# WKUP_CTRL_MMR0_CFG0 register map
Vendor: Texas Instruments
Registers are 32-bit, read-write, reset 0x0 unless marked. A register's access mark holds for its fields unless they carry their own. Offsets are as the file gives them; [hi:lo] are bit positions; lines under a group give offsets from that group; {n}, {i} and the like mark numbered series.

## WKUP_CTRL_MMR0_CFG0 (part 4 of 11)
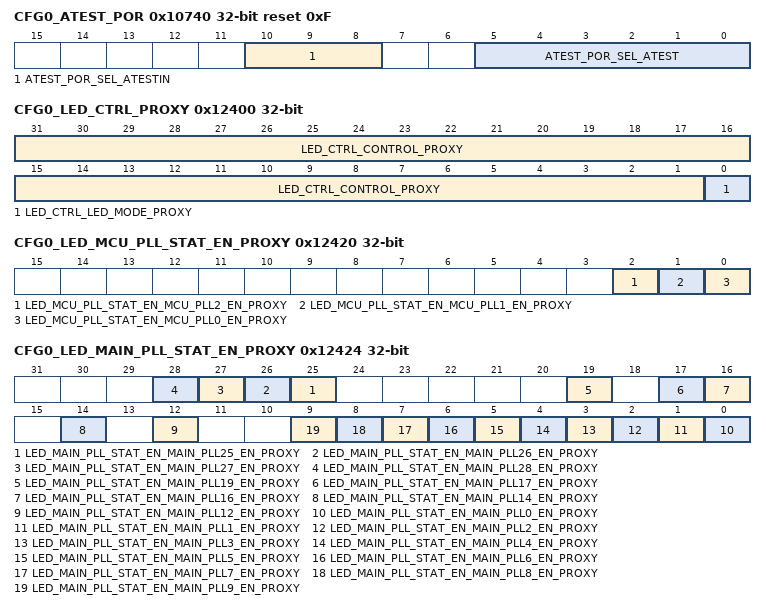
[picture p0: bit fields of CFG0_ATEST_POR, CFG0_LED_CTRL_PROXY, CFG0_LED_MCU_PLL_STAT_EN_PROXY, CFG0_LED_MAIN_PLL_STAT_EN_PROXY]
0x10740 CFG0_ATEST_POR reset 0xF
  [10:8] ATEST_POR_SEL_ATESTIN — Test select 3'b000 - Test Modes 0-4, See sel_atest value 3'b001 - Test Mode 5 when sel_atest = 6'b001111 Others - N/A (Hi-Z at ATEST_OUT)
  [5:0] ATEST_POR_SEL_ATEST — Test select 6'b000000 to 001010 - Bandgap TestT (Test Mode 1) 6'b001001 to 001111 - Hi-Z (when sel_atestin = 3'b000) 6'b001001 to 001111 - HVPOR Test (when sel_atestin = 3'b001) 6'b01xx00 to 01xx11 - POKHV Test (Test Mode 2) 6'b10xx00 to 10xx11 - POKLVA Test (Test mode 3) 6'b11xx00 - 11xx11 - POKLVB Test (Test Mode 4)
0x10744 CFG0_ATEST_POK_VDDA_MCU_UV_CTRL
  [2:0] ATEST_POK_VDDA_MCU_UV_CTRL_POK_ATMUXSEL — Analog test mux select 2'b000 - HI-Z 2'b001 - IREF 2'b101 - VREF 2'b111 - RESDIV_VREF
0x10748 CFG0_ATEST_POK_VDDA_MCU_OV_CTRL
  [2:0] ATEST_POK_VDDA_MCU_OV_CTRL_POK_ATMUXSEL — Analog test mux select 2'b000 - HI-Z 2'b001 - IREF 2'b101 - VREF 2'b111 - RESDIV_VREF
0x1074C CFG0_ATEST_POK_VDD_MCU_UV_CTRL
  [2:0] ATEST_POK_VDD_MCU_UV_CTRL_POK_ATMUXSEL — Analog test mux select 2'b000 - HI-Z 2'b001 - IREF 2'b101 - VREF 2'b111 - RESDIV_VREF
0x10750 CFG0_ATEST_POK_VDDA_PMIC_IN
  [2:0] ATEST_POK_VDDA_PMIC_IN_POK_ATMUXSEL — Analog test mux select 2'b000 - HI-Z 2'b001 - IREF 2'b101 - VREF 2'b111 - RESDIV_VREF
0x10754 CFG0_ATEST_POK_VDD_MCU_OV_CTRL
  [2:0] ATEST_POK_VDD_MCU_OV_CTRL_POK_ATMUXSEL — Analog test mux select 2'b000 - HI-Z 2'b001 - IREF 2'b101 - VREF 2'b111 - RESDIV_VREF
0x10760 CFG0_ATEST_POK_VDDSHV_WKUP_GEN_CTRL
  [2:0] ATEST_POK_VDDSHV_WKUP_GEN_CTRL_POK_ATMUXSEL — Analog test mux select 2'b000 - HI-Z 2'b001 - IREF 2'b101 - VREF 2'b111 - RESDIV_VREF
0x10764 CFG0_ATEST_POK_VDDR_MCU_CTRL
  [2:0] ATEST_POK_VDDR_MCU_CTRL_POK_ATMUXSEL — Analog test mux select 2'b000 - HI-Z 2'b001 - IREF 2'b101 - VREF 2'b111 - RESDIV_VREF
0x10768 CFG0_ATEST_POK_VMON_CAP_MCU_GEN_CTRL
  [2:0] ATEST_POK_VMON_CAP_MCU_GEN_CTRL_POK_ATMUXSEL — Analog test mux select 2'b000 - HI-Z 2'b001 - IREF 2'b101 - VREF 2'b111 - RESDIV_VREF
0x10780 CFG0_ATEST_POK_VDD_CORE_CTRL
  [2:0] ATEST_POK_VDD_CORE_CTRL_POK_ATMUXSEL — Analog test mux select 2'b000 - HI-Z 2'b001 - IREF 2'b101 - VREF 2'b111 - RESDIV_VREF
0x10784 CFG0_ATEST_POK_VDD_CPU_CTRL
  [2:0] ATEST_POK_VDD_CPU_CTRL_POK_ATMUXSEL — Analog test mux select 2'b000 - HI-Z 2'b001 - IREF 2'b101 - VREF 2'b111 - RESDIV_VREF
0x10788 CFG0_ATEST_POK_VMON_EXT_CTRL
  [2:0] ATEST_POK_VMON_EXT_CTRL_POK_ATMUXSEL — Analog test mux select 2'b000 - HI-Z 2'b001 - IREF 2'b101 - VREF 2'b111 - RESDIV_VREF
0x1078C CFG0_ATEST_POK_VDDR_CORE_CTRL
  [2:0] ATEST_POK_VDDR_CORE_CTRL_POK_ATMUXSEL — Analog test mux select 2'b000 - HI-Z 2'b001 - IREF 2'b101 - VREF 2'b111 - RESDIV_VREF
0x10790 CFG0_ATEST_POK_VMON_EXT_MAIN1P8_CTRL
  [2:0] ATEST_POK_VMON_EXT_MAIN1P8_CTRL_POK_ATMUXSEL — Analog test mux select 2'b000 - HI-Z 2'b001 - IREF 2'b101 - VREF 2'b111 - RESDIV_VREF
0x10794 CFG0_ATEST_POK_VMON_EXT_MAIN3P3_CTRL
  [2:0] ATEST_POK_VMON_EXT_MAIN3P3_CTRL_POK_ATMUXSEL — Analog test mux select 2'b000 - HI-Z 2'b001 - IREF 2'b101 - VREF 2'b111 - RESDIV_VREF
0x10798 CFG0_ATEST_POK_VDD_CPU1_CTRL
  [2:0] ATEST_POK_VDD_CPU1_CTRL_POK_ATMUXSEL — Analog test mux select 2'b000 - HI-Z 2'b001 - IREF 2'b101 - VREF 2'b111 - RESDIV_VREF
{0x11100+4i} CFG0_CLAIMREG_P4_R{i}_READONLY ro (i=0..15)
  [31:0] CLAIMREG_P4_R{i}_READONLY — Claim bits for Partition 4
{0x12000+4i} CFG0_DV_REG{i}_PROXY (i=0..63)
  [31:0] DV_REG{i}_BIT_PROXY — Defined by DV usage
{0x12200+4i} CFG0_DV_REG{i}_SET_PROXY access not given (i=0..31)
  [31:0] DV_REG{i}_SET_BIT_PROXY — Defined by DV usage (access R/W1TS)
{0x12300+4i} CFG0_DV_REG{i}_CLR_PROXY access not given (i=0..31)
  [31:0] DV_REG{i}_CLR_BIT_PROXY — Defined by DV usage (access R/W1TC)
0x12400 CFG0_LED_CTRL_PROXY access per field
  [31:1] LED_CTRL_CONTROL_PROXY rw — Test control
  [0] LED_CTRL_LED_MODE_PROXY ro — LED mode from decoded enable key
0x12408 CFG0_LED_ENABLE_PROXY
  [31:0] LED_ENABLE_ENABLE_KEY_PROXY — LED mode entry key 32'h204C4544 - Set PADCONFIG registers to LED mode values others - PADCONFIG registers retain programmed values
0x12420 CFG0_LED_MCU_PLL_STAT_EN_PROXY
  [2] LED_MCU_PLL_STAT_EN_MCU_PLL2_EN_PROXY — Enable MCU_PLL2 lockloss in status generation
  [1] LED_MCU_PLL_STAT_EN_MCU_PLL1_EN_PROXY — Enable MCU_PLL1 lockloss in status generation
  [0] LED_MCU_PLL_STAT_EN_MCU_PLL0_EN_PROXY — Enable MCU_PLL0 lockloss in status generation
0x12424 CFG0_LED_MAIN_PLL_STAT_EN_PROXY
  [n] LED_MAIN_PLL_STAT_EN_MAIN_PLL{n}_EN_PROXY (n=25..28) — Enable MAIN_PLL{n} lockloss in status generation
  [19] LED_MAIN_PLL_STAT_EN_MAIN_PLL19_EN_PROXY — Enable MAIN_PLL19 lockloss in status generation
  [17] LED_MAIN_PLL_STAT_EN_MAIN_PLL17_EN_PROXY — Enable MAIN_PLL17 lockloss in status generation
  [16] LED_MAIN_PLL_STAT_EN_MAIN_PLL16_EN_PROXY — Enable MAIN_PLL16 lockloss in status generation
  [14] LED_MAIN_PLL_STAT_EN_MAIN_PLL14_EN_PROXY — Enable MAIN_PLL14 lockloss in status generation
  [12] LED_MAIN_PLL_STAT_EN_MAIN_PLL12_EN_PROXY — Enable MAIN_PLL12 lockloss in status generation
  [n] LED_MAIN_PLL_STAT_EN_MAIN_PLL{n}_EN_PROXY (n=0..9) — Enable MAIN_PLL{n} lockloss in status generation
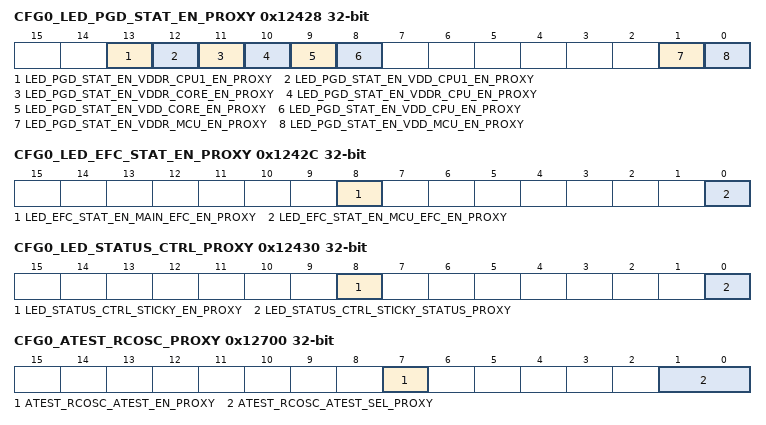
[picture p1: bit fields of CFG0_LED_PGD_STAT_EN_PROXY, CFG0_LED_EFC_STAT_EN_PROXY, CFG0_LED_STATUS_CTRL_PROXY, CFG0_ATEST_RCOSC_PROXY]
0x12428 CFG0_LED_PGD_STAT_EN_PROXY
  [13] LED_PGD_STAT_EN_VDDR_CPU1_EN_PROXY — Enable vddr_cpu1 PGD in status generation
  [12] LED_PGD_STAT_EN_VDD_CPU1_EN_PROXY — Enable vdd_cpu1 PGD in status generation
  [11] LED_PGD_STAT_EN_VDDR_CORE_EN_PROXY — Enable vddr_core PGD in status generation
  [10] LED_PGD_STAT_EN_VDDR_CPU_EN_PROXY — Enable vddr_cpu PGD in status generation
  [9] LED_PGD_STAT_EN_VDD_CORE_EN_PROXY — Enable vdd_core PGD in status generation
  [8] LED_PGD_STAT_EN_VDD_CPU_EN_PROXY — Enable vdd_cpu PGD in status generation
  [1] LED_PGD_STAT_EN_VDDR_MCU_EN_PROXY — Enable vddr_mcu PGD in status generation
  [0] LED_PGD_STAT_EN_VDD_MCU_EN_PROXY — Enable vdd_mcu PGD in status generation
0x1242C CFG0_LED_EFC_STAT_EN_PROXY
  [8] LED_EFC_STAT_EN_MAIN_EFC_EN_PROXY — Enable MAIN eFuse Ctrl PGD in status generation
  [0] LED_EFC_STAT_EN_MCU_EFC_EN_PROXY — Enable MCU eFuse Ctrl PGD in status generation
0x12430 CFG0_LED_STATUS_CTRL_PROXY
  [8] LED_STATUS_CTRL_STICKY_EN_PROXY — Sticky status enable. Selects which version of status to output on the pin. 0 - Use real-time status signal 1 - Use sticky status signal
  [0] LED_STATUS_CTRL_STICKY_STATUS_PROXY — Sticky status bit. This bit captures the falling edge of the status signal
{0x12480+4i} CFG0_SIM_CFG{i}_PROXY (i=0..7)
  [31:0] SIM_CFG{i}_CFG_INFO_PROXY — Model configuration info. Bit usage is determined by AVV team.
0x12500 CFG0_WKUP_MRGN_MODE0_PROXY
  [11:0] WKUP_MRGN_MODE0_HS2PARF_MEM_MRGN_ASST_PROXY — DFT memory margin control Bits 0-3 - dft_mem_margin Bits 4-5 - dft_mem_ra Bits 6-8 - dft_mem_wa Bits 9-11 - dft_wpulse
0x12504 CFG0_WKUP_MRGN_MODE1_PROXY
  [11:0] WKUP_MRGN_MODE1_HDDP_MEM_MRGN_ASST_PROXY — DFT memory margin control Bits 0-3 - dft_mem_margin Bits 4-5 - dft_mem_ra Bits 6-8 - dft_mem_wa Bits 9-11 - dft_wpulse
0x12508 CFG0_WKUP_MRGN_MODE2_PROXY
  [11:0] WKUP_MRGN_MODE2_EHDSP_MEM_MRGN_ASST_PROXY — DFT memory margin control Bits 0-3 - dft_mem_margin Bits 4-5 - dft_mem_ra Bits 6-8 - dft_mem_wa Bits 9-11 - dft_wpulse
0x1250C CFG0_WKUP_MRGN_MODE3_PROXY
  [11:0] WKUP_MRGN_MODE3_HD2PRF_MEM_MRGN_ASST_PROXY — DFT memory margin control Bits 0-3 - dft_mem_margin Bits 4-5 - dft_mem_ra Bits 6-8 - dft_mem_wa Bits 9-11 - dft_wpulse
0x12510 CFG0_WKUP_MRGN_MODE4_PROXY
  [11:0] WKUP_MRGN_MODE4_UHD2PRF_MEM_MRGN_ASST_PROXY — DFT memory margin control Bits 0-3 - dft_mem_margin Bits 4-5 - dft_mem_ra Bits 6-8 - dft_mem_wa Bits 9-11 - dft_wpulse
0x12514 CFG0_WKUP_MRGN_MODE5_PROXY
  [11:0] WKUP_MRGN_MODE5_ROM_MEM_MRGN_ASST_PROXY — DFT memory margin control Bits 0-3 - dft_mem_margin Bits 4-5 - dft_mem_ra Bits 6-8 - dft_mem_wa Bits 9-11 - dft_wpulse
0x12518 CFG0_WKUP_MRGN_MODE6_PROXY
  [11:0] WKUP_MRGN_MODE6_HDSP_MEM_MRGN_ASST_PROXY — DFT memory margin control Bits 0-3 - dft_mem_margin Bits 4-5 - dft_mem_ra Bits 6-8 - dft_mem_wa Bits 9-11 - dft_wpulse
0x1251C CFG0_WKUP_MRGN_MODE7_PROXY
  [11:0] WKUP_MRGN_MODE7_HSSP_MEM_MRGN_ASST_PROXY — DFT memory margin control Bits 0-3 - dft_mem_margin Bits 4-5 - dft_mem_ra Bits 6-8 - dft_mem_wa Bits 9-11 - dft_wpulse
0x12520 CFG0_WKUP_MRGN_MODE8_PROXY
  [11:0] WKUP_MRGN_MODE8_HD1PRF_MEM_MRGN_ASST_PROXY — DFT memory margin control Bits 0-3 - dft_mem_margin Bits 4-5 - dft_mem_ra Bits 6-8 - dft_mem_wa Bits 9-11 - dft_wpulse
0x12524 CFG0_WKUP_MRGN_MODE9_PROXY
  [11:0] WKUP_MRGN_MODE9_HS1PRF_MEM_MRGN_ASST_PROXY — DFT memory margin control Bits 0-3 - dft_mem_margin Bits 4-5 - dft_mem_ra Bits 6-8 - dft_mem_wa Bits 9-11 - dft_wpulse
0x12700 CFG0_ATEST_RCOSC_PROXY
  [7] ATEST_RCOSC_ATEST_EN_PROXY — Test enable 1'b0 - Disable (atestout is floating) 1'b1 - Enable (see atest_test)
  [1:0] ATEST_RCOSC_ATEST_SEL_PROXY — Test select When atest_en = 1 2'b0x - Hi-Z (Test 3) 2'b10 - Bias current (Test 1) 2'b11 - VREF (Test 2)
0x12720 CFG0_ATEST_HFOSC0_PROXY
  [0] ATEST_HFOSC0_TEST_EN_C_PROXY — Test enable 1'b0 - Output test current disabled 1'b1 - Test current enabled
0x12724 CFG0_ATEST_HFOSC1_PROXY
  [0] ATEST_HFOSC1_TEST_EN_C_PROXY — Test enable 1'b0 - Output test current disabled 1'b1 - Test current enabled
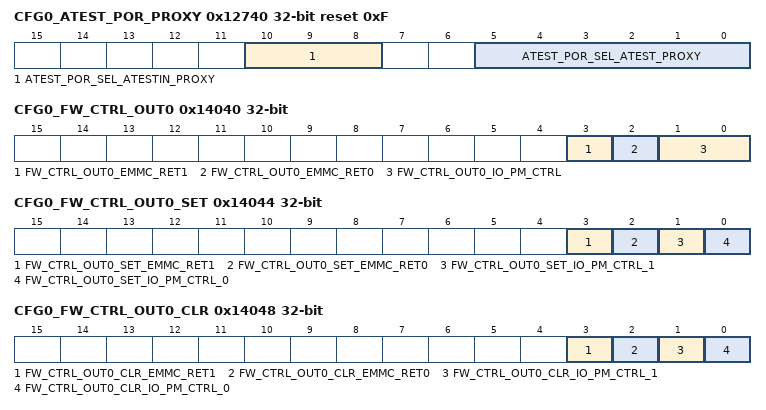
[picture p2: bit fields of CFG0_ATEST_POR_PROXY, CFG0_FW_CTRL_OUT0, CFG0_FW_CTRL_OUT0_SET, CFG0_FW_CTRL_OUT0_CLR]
0x12740 CFG0_ATEST_POR_PROXY reset 0xF
  [10:8] ATEST_POR_SEL_ATESTIN_PROXY — Test select 3'b000 - Test Modes 0-4, See sel_atest value 3'b001 - Test Mode 5 when sel_atest = 6'b001111 Others - N/A (Hi-Z at ATEST_OUT)
  [5:0] ATEST_POR_SEL_ATEST_PROXY — Test select 6'b000000 to 001010 - Bandgap TestT (Test Mode 1) 6'b001001 to 001111 - Hi-Z (when sel_atestin = 3'b000) 6'b001001 to 001111 - HVPOR Test (when sel_atestin = 3'b001) 6'b01xx00 to 01xx11 - POKHV Test (Test Mode 2) 6'b10xx00 to 10xx11 - POKLVA Test (Test mode 3) 6'b11xx00 - 11xx11 - POKLVB Test (Test Mode 4)
0x12744 CFG0_ATEST_POK_VDDA_MCU_UV_CTRL_PROXY
  [2:0] ATEST_POK_VDDA_MCU_UV_CTRL_POK_ATMUXSEL_PROXY — Analog test mux select 2'b000 - HI-Z 2'b001 - IREF 2'b101 - VREF 2'b111 - RESDIV_VREF
0x12748 CFG0_ATEST_POK_VDDA_MCU_OV_CTRL_PROXY
  [2:0] ATEST_POK_VDDA_MCU_OV_CTRL_POK_ATMUXSEL_PROXY — Analog test mux select 2'b000 - HI-Z 2'b001 - IREF 2'b101 - VREF 2'b111 - RESDIV_VREF
0x1274C CFG0_ATEST_POK_VDD_MCU_UV_CTRL_PROXY
  [2:0] ATEST_POK_VDD_MCU_UV_CTRL_POK_ATMUXSEL_PROXY — Analog test mux select 2'b000 - HI-Z 2'b001 - IREF 2'b101 - VREF 2'b111 - RESDIV_VREF
0x12750 CFG0_ATEST_POK_VDDA_PMIC_IN_PROXY
  [2:0] ATEST_POK_VDDA_PMIC_IN_POK_ATMUXSEL_PROXY — Analog test mux select 2'b000 - HI-Z 2'b001 - IREF 2'b101 - VREF 2'b111 - RESDIV_VREF
0x12754 CFG0_ATEST_POK_VDD_MCU_OV_CTRL_PROXY
  [2:0] ATEST_POK_VDD_MCU_OV_CTRL_POK_ATMUXSEL_PROXY — Analog test mux select 2'b000 - HI-Z 2'b001 - IREF 2'b101 - VREF 2'b111 - RESDIV_VREF
0x12760 CFG0_ATEST_POK_VDDSHV_WKUP_GEN_CTRL_PROXY
  [2:0] ATEST_POK_VDDSHV_WKUP_GEN_CTRL_POK_ATMUXSEL_PROXY — Analog test mux select 2'b000 - HI-Z 2'b001 - IREF 2'b101 - VREF 2'b111 - RESDIV_VREF
0x12764 CFG0_ATEST_POK_VDDR_MCU_CTRL_PROXY
  [2:0] ATEST_POK_VDDR_MCU_CTRL_POK_ATMUXSEL_PROXY — Analog test mux select 2'b000 - HI-Z 2'b001 - IREF 2'b101 - VREF 2'b111 - RESDIV_VREF
0x12768 CFG0_ATEST_POK_VMON_CAP_MCU_GEN_CTRL_PROXY
  [2:0] ATEST_POK_VMON_CAP_MCU_GEN_CTRL_POK_ATMUXSEL_PROXY — Analog test mux select 2'b000 - HI-Z 2'b001 - IREF 2'b101 - VREF 2'b111 - RESDIV_VREF
0x12780 CFG0_ATEST_POK_VDD_CORE_CTRL_PROXY
  [2:0] ATEST_POK_VDD_CORE_CTRL_POK_ATMUXSEL_PROXY — Analog test mux select 2'b000 - HI-Z 2'b001 - IREF 2'b101 - VREF 2'b111 - RESDIV_VREF
0x12784 CFG0_ATEST_POK_VDD_CPU_CTRL_PROXY
  [2:0] ATEST_POK_VDD_CPU_CTRL_POK_ATMUXSEL_PROXY — Analog test mux select 2'b000 - HI-Z 2'b001 - IREF 2'b101 - VREF 2'b111 - RESDIV_VREF
0x12788 CFG0_ATEST_POK_VMON_EXT_CTRL_PROXY
  [2:0] ATEST_POK_VMON_EXT_CTRL_POK_ATMUXSEL_PROXY — Analog test mux select 2'b000 - HI-Z 2'b001 - IREF 2'b101 - VREF 2'b111 - RESDIV_VREF
0x1278C CFG0_ATEST_POK_VDDR_CORE_CTRL_PROXY
  [2:0] ATEST_POK_VDDR_CORE_CTRL_POK_ATMUXSEL_PROXY — Analog test mux select 2'b000 - HI-Z 2'b001 - IREF 2'b101 - VREF 2'b111 - RESDIV_VREF
0x12790 CFG0_ATEST_POK_VMON_EXT_MAIN1P8_CTRL_PROXY
  [2:0] ATEST_POK_VMON_EXT_MAIN1P8_CTRL_POK_ATMUXSEL_PROXY — Analog test mux select 2'b000 - HI-Z 2'b001 - IREF 2'b101 - VREF 2'b111 - RESDIV_VREF
0x12794 CFG0_ATEST_POK_VMON_EXT_MAIN3P3_CTRL_PROXY
  [2:0] ATEST_POK_VMON_EXT_MAIN3P3_CTRL_POK_ATMUXSEL_PROXY — Analog test mux select 2'b000 - HI-Z 2'b001 - IREF 2'b101 - VREF 2'b111 - RESDIV_VREF
0x12798 CFG0_ATEST_POK_VDD_CPU1_CTRL_PROXY
  [2:0] ATEST_POK_VDD_CPU1_CTRL_POK_ATMUXSEL_PROXY — Analog test mux select 2'b000 - HI-Z 2'b001 - IREF 2'b101 - VREF 2'b111 - RESDIV_VREF
{0x13100+4i} CFG0_CLAIMREG_P4_R{i} (i=0..15)
  [31:0] CLAIMREG_P4_R{i} — Claim bits for Partition 4
0x14040 CFG0_FW_CTRL_OUT0 ro
  [3] FW_CTRL_OUT0_EMMC_RET1 — Reflects the value of the corresponding bit in fw_ctrl_out SMS output bus. This bit is used by SOC to drive an AO signal that will eventually be expanded into a complementary pair (RET + RET_B) at the boundary of EMMC-PHY instance 1
  [2] FW_CTRL_OUT0_EMMC_RET0 — Reflects the value of the corresponding bit in fw_ctrl_out SMS output bus. This bit is used by SOC to drive an AO signal that will eventually be expanded into a complementary pair (RET + RET_B) at the boundary of EMMC-PHY instance 0
  [1:0] FW_CTRL_OUT0_IO_PM_CTRL — This value is used by DMSC/SMS firmware to apply the DS (deep/deeper-sleep) values at once by qualifying the generation of the integration signal to the dsen_qualified to the IOs. These 2 bits are used in conjunction with those in the PMCTRL_IO_1/0 MMRs. The values gated/applied by dsen_qualified are those defined on the PADCONFIG MMR for each IO pad, as the DS selections, for the following IO pins: pupdsel, pi, txout, gz 0 - The active/normal mode pad-config defined values are applied to each IO/IO-pad that is part of the IO-PM daisy chain. 1 - The DS value, defined in the pad-config is applied to each IO/IO-pad that is part of the IO-PM daisy chain The io_pm_ctrl0 Is used to control deep/deeper-sleep values for the IOs in the WKUP section of the SOC. The io_pm_ctrl1 Is used to control deep/deeper-sleep values for the IOs in the MAIN section of the SOC.
0x14044 CFG0_FW_CTRL_OUT0_SET access not given
  [3] FW_CTRL_OUT0_SET_EMMC_RET1 — Sets the value of the corresponding bit in fw_ctrl_out SMS output bus. This bit is used by SOC to drive an AO signal that will eventually be expanded into a complementary pair (RET + RET_B) at the boundary of EMMC-PHY instance1 (access R/W1TS)
  [2] FW_CTRL_OUT0_SET_EMMC_RET0 — Sets the value of the corresponding bit in fw_ctrl_out SMS output bus. This bit is used by SOC to drive an AO signal that will eventually be expanded into a complementary pair (RET + RET_B) at the boundary of EMMC-PHY instance 0 (access R/W1TS)
  [1] FW_CTRL_OUT0_SET_IO_PM_CTRL_1 — This MMR bit is a W1ts bit field for MMR-bit-field FW_CTRL_OUT0.io_pm_ctrl1 (access R/W1TS)
  [0] FW_CTRL_OUT0_SET_IO_PM_CTRL_0 — This MMR bit is a W1ts bit field for MMR-bit-field FW_CTRL_OUT0.io_pm_ctrl0 (access R/W1TS)
0x14048 CFG0_FW_CTRL_OUT0_CLR access not given
  [3] FW_CTRL_OUT0_CLR_EMMC_RET1 — Clears the value of the corresponding bit in fw_ctrl_out SMS output bus. This bit is used by SOC to drive an AO signal that will eventually be expanded into a complementary pair (RET + RET_B) at the boundary of EMMC-PHY instance1. (access R/W1TC)
  [2] FW_CTRL_OUT0_CLR_EMMC_RET0 — Clears the value of the corresponding bit in fw_ctrl_out SMS output bus. This bit is used by SOC to drive an AO signal that will eventually be expanded into a complementary pair (RET + RET_B) at the boundary of EMMC-PHY instance 0 (access R/W1TC)
  [1] FW_CTRL_OUT0_CLR_IO_PM_CTRL_1 — This MMR bit is a W1ts bit field for MMR-bit-field FW_CTRL_OUT0.io_pm_ctrl1 (access R/W1TC)
  [0] FW_CTRL_OUT0_CLR_IO_PM_CTRL_0 — This MMR bit is a W1ts bit field for MMR-bit-field FW_CTRL_OUT0.io_pm_ctrl0 (access R/W1TC)
0x14080 CFG0_PMCTRL_SYS reset 0x10
  [4] PMCTRL_SYS_PMIC_EN — PMIC enable. In order to write to this field, you need to write 1 in the same access to field pmic_en_we. NOTE: This MMR bit does not reflect any contribution from any debug related signal. 0 - Drives PMIC_EN output port to 0, unless there is an POWER-OFF inhibit condition due to Debug/Security 1 - Drives PMIC_EN output port to 1, if not already 1
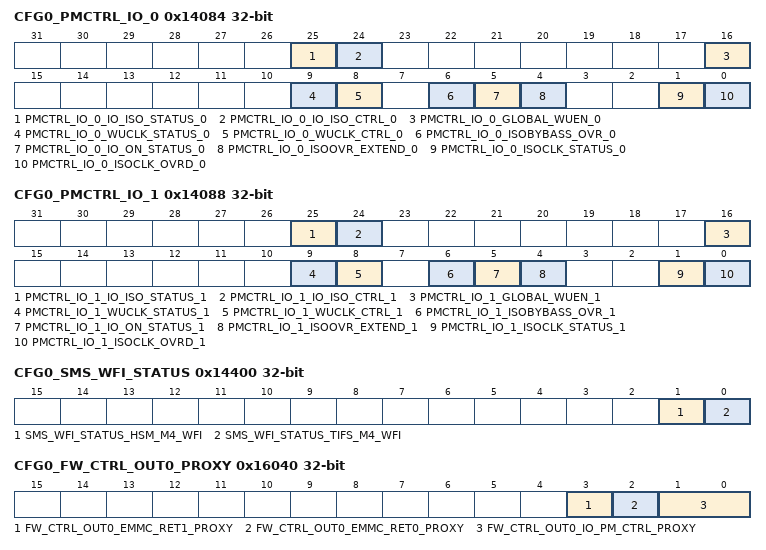
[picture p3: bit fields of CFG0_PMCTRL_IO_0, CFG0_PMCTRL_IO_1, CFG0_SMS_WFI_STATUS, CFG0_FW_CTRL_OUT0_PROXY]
0x14084 CFG0_PMCTRL_IO_0 access per field
  [25] PMCTRL_IO_0_IO_ISO_STATUS_0 ro — IO ISO Status 0 - IO isolation not active 1 - IO isolation active. Reflects value of SMS input port io_isoack coming back from IO pad ring
  [24] PMCTRL_IO_0_IO_ISO_CTRL_0 rw — IO ISO control. 0 - Turn off the IO isolation 1 - Turn on the IO isolation
  [16] PMCTRL_IO_0_GLOBAL_WUEN_0 rw — Global IO wakeup enable. This is a gating condition to all individual IO WUEN coming from control module. Gating is done in the Spinner logic. 0 - All individual IO WUEN are gated in the Spinner logic (override to 0). 1 - All individual IO WUEN from control module are going to IOs. Maps to SMS output port io_globalwkupen0 .
  [9] PMCTRL_IO_0_WUCLK_STATUS_0 ro — Reflects value of SMS input port io_wuclkack coming back from IO pad ring
  [8] PMCTRL_IO_0_WUCLK_CTRL_0 rw — Direct control on WUCLKIN signal to IO pad ring. 0 - WUCLKIN signal is driven to 0. IO wakeup daisy chain is functional as well as IO whose wakeup feature is enabled. 1 - WUCLKIN signal is driven to 1. IO wakeup daisy chain is reset and is latching current pad states and WUEN inputs
  [6] PMCTRL_IO_0_ISOBYBASS_OVR_0 rw — This MMR bit drives directly SMS output port io_isobypass0.
  [5] PMCTRL_IO_0_IO_ON_STATUS_0 ro — Gives the functional status of the IO ring. 0 - Part or all of the IOs are not in the ON state that is are in isolation state. 1 - All IOs are in the ON state. io_on_status = assign 1 if (io_iso == 0 & io_isoack==0 & io_iso_clk == 0 & io_isoclk_ack = 0 ) else 0;
  [4] PMCTRL_IO_0_ISOOVR_EXTEND_0 rw — Control for IO isolation extension This drives the SOC chain ISO-OVERRIDE global control. This bit drives directly the SMS output port io_isoovr0. At the SOC level it is used to enable when 1 or gate-off when 0, the individual ISOOR for each IO. This operates as a global enable/disable for the individual IOs. 0 - IO isolation is not extended. Transition happens as soon as automatic restore is completed. 1 - IO isolation is extended. The IOs whose ISOOVR bits have been individually set in their PADCFG MMRs will all get its IO isolation extended beyond the point when the initial IO daisy chain isolation is released.
  [1] PMCTRL_IO_0_ISOCLK_STATUS_0 ro — Reflects value of io_isoclkack coming back from IO pad ring.
  [0] PMCTRL_IO_0_ISOCLK_OVRD_0 rw — Override control on ISOCLKIN signal to IO pad ring. When not overridden this signal is controlled by hardware only. 0 - ISOCLKIN signal is not overriden. 1 - ISOCLKIN signal is overridden to active value (1).
0x14088 CFG0_PMCTRL_IO_1 access per field
  [25] PMCTRL_IO_1_IO_ISO_STATUS_1 ro — IO ISO Status 0 - IO isolation not active 1 - IO isolation active. Reflects value of SMS input port io_isoack coming back from IO pad ring
  [24] PMCTRL_IO_1_IO_ISO_CTRL_1 rw — IO ISO control. 0 - Turn off the IO isolation 1 - Turn on the IO isolation
  [16] PMCTRL_IO_1_GLOBAL_WUEN_1 rw — Global IO wakeup enable. This is a gating condition to all individual IO WUEN coming from control module. Gating is done in the Spinner logic. 0 - All individual IO WUEN are gated in the Spinner logic (override to 0). 1 - All individual IO WUEN from control module are going to IOs. Maps to SMS output port io_globalwkupen1 .
  [9] PMCTRL_IO_1_WUCLK_STATUS_1 ro — Reflects value of SMS input port io_wuclkack coming back from IO pad ring
  [8] PMCTRL_IO_1_WUCLK_CTRL_1 rw — Direct control on WUCLKIN signal to IO pad ring. 0 - WUCLKIN signal is driven to 0. IO wakeup daisy chain is functional as well as IO whose wakeup feature is enabled. 1 - WUCLKIN signal is driven to 1. IO wakeup daisy chain is reset and is latching current pad states and WUEN inputs
  [6] PMCTRL_IO_1_ISOBYBASS_OVR_1 rw — This MMR bit drives directly SMS output port io_isobypassundefined.
  [5] PMCTRL_IO_1_IO_ON_STATUS_1 ro — Gives the functional status of the IO ring. 0 - Part or all of the IOs are not in the ON state that is are in isolation state. 1 - All IOs are in the ON state. io_on_status = assign 1 if (io_iso == 0 & io_isoack==0 & io_iso_clk == 0 & io_isoclk_ack = 0 ) else 0;
  [4] PMCTRL_IO_1_ISOOVR_EXTEND_1 rw — Control for IO isolation extension This drives the SOC chain ISO-OVERRIDE global control. This bit drives directly the SMS output port io_isoovrundefined. At the SOC level it is used to enable when 1 or gate-off when 0, the individual ISOOR for each IO. This operates as a global enable/disable for the individual IOs. 0 - IO isolation is not extended. Transition happens as soon as automatic restore is completed. 1 - IO isolation is extended. The IOs whose ISOOVR bits have been individually set in their PADCFG MMRs will all get its IO isolation extended beyond the point when the initial IO daisy chain isolation is released.
  [1] PMCTRL_IO_1_ISOCLK_STATUS_1 ro — Reflects value of io_isoclkack coming back from IO pad ring.
  [0] PMCTRL_IO_1_ISOCLK_OVRD_1 rw — Override control on ISOCLKIN signal to IO pad ring. When not overridden this signal is controlled by hardware only. 0 - ISOCLKIN signal is not overriden. 1 - ISOCLKIN signal is overridden to active value (1).
0x14300 CFG0_PM_PERMISSION ro
  [0] PM_PERMISSION_DEBUG_ACTIVE — Debug mode activated Tells PM-FW that it should not power-OFF supplies externally. The debugger being active should also cause the SMS hardware to override the external rail state during deeperSleep by forcing high the pmic_en output. In addition to forcing the rails of all SOC supplies on, this bit will also cause the VDD_CORE domain in SOCs with it, to get out of POR-reset and wake-up the Debugss so that its JTAG interface can connect. When this MMR bit is set, PM Hardware FSM should enter only into low power modes LPM0 to LPM1, but should not go into LPM2 to LPM4 where it clock-gates or power downs the clock sources. The debug_activated input set to '1' will also cause the M4 to get out of LPMs and exit WFI, since there is an interrupt allocated to that input port (debug_activated), after the attached debug is disconnected from the SOC the interrupt associated to debug_deactivated will be triggered by IceMelter and that should cause the M4 to exit the debug_activated interrupt service routine (ISR), and , if no other wake-up event is present then when debug_deactivated goes to '0' the PM-FW will do any required clearing/cleaning as part of the ISR set the M4 in WFI, and return to the low power state as defined in PMCTRL_SYS.LPM[2:0] bits. If instead of an attached debugger being present we have a software driven debug, then the interrupt that could be triggered instead of debug_activated will be debug_forceactive_int and causing same response as with debug_activated input/interrupt. In this case as part of the debug_activated ISR epilog the M4 will go back to WFI, , and return to the low power state as defined in PMCTRL_SYS.LPM[2:0] bits. 0 - Debug not activated 1 - Debug activated
0x14400 CFG0_SMS_WFI_STATUS ro
  [1] SMS_WFI_STATUS_HSM_M4_WFI — Indicates WFI status of the HSM M4 processor in SMS 0 - Normal operation 1 - M4 is in WFI state
  [0] SMS_WFI_STATUS_TIFS_M4_WFI — Indicates WFI status of the TIFS M4 processor in SMS 0 - Normal operation 1 - M4 is in WFI state
{0x15100+4i} CFG0_CLAIMREG_P5_R{i}_READONLY ro (i=0..8)
  [31:0] CLAIMREG_P5_R{i}_READONLY — Claim bits for Partition 5
0x16040 CFG0_FW_CTRL_OUT0_PROXY ro
  [3] FW_CTRL_OUT0_EMMC_RET1_PROXY — Reflects the value of the corresponding bit in fw_ctrl_out SMS output bus. This bit is used by SOC to drive an AO signal that will eventually be expanded into a complementary pair (RET + RET_B) at the boundary of EMMC-PHY instance 1
  [2] FW_CTRL_OUT0_EMMC_RET0_PROXY — Reflects the value of the corresponding bit in fw_ctrl_out SMS output bus. This bit is used by SOC to drive an AO signal that will eventually be expanded into a complementary pair (RET + RET_B) at the boundary of EMMC-PHY instance 0
  [1:0] FW_CTRL_OUT0_IO_PM_CTRL_PROXY — This value is used by DMSC/SMS firmware to apply the DS (deep/deeper-sleep) values at once by qualifying the generation of the integration signal to the dsen_qualified to the IOs. These 2 bits are used in conjunction with those in the PMCTRL_IO_1/0 MMRs. The values gated/applied by dsen_qualified are those defined on the PADCONFIG MMR for each IO pad, as the DS selections, for the following IO pins: pupdsel, pi, txout, gz 0 - The active/normal mode pad-config defined values are applied to each IO/IO-pad that is part of the IO-PM daisy chain. 1 - The DS value, defined in the pad-config is applied to each IO/IO-pad that is part of the IO-PM daisy chain The io_pm_ctrl0 Is used to control deep/deeper-sleep values for the IOs in the WKUP section of the SOC. The io_pm_ctrl1 Is used to control deep/deeper-sleep values for the IOs in the MAIN section of the SOC.
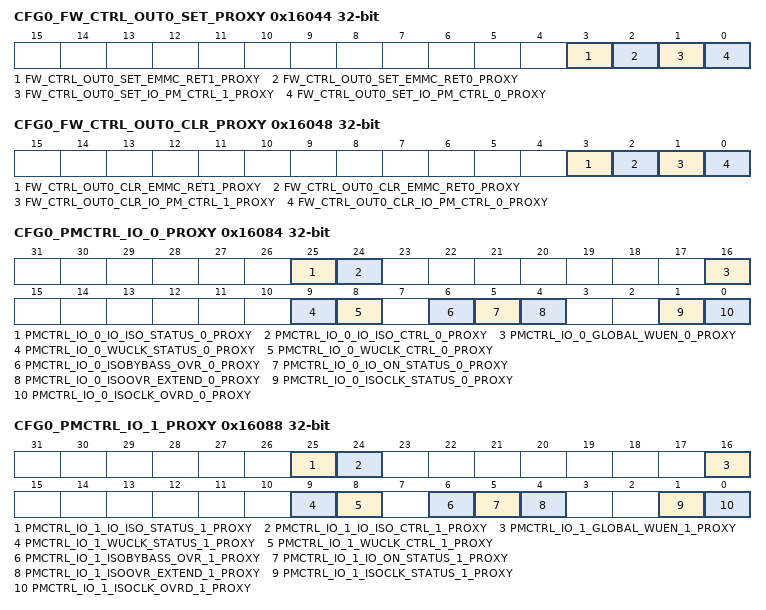
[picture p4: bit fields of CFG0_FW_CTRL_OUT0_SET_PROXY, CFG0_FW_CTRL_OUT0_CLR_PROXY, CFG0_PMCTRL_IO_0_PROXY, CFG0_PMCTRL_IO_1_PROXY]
0x16044 CFG0_FW_CTRL_OUT0_SET_PROXY access not given
  [3] FW_CTRL_OUT0_SET_EMMC_RET1_PROXY — Sets the value of the corresponding bit in fw_ctrl_out SMS output bus. This bit is used by SOC to drive an AO signal that will eventually be expanded into a complementary pair (RET + RET_B) at the boundary of EMMC-PHY instance1 (access R/W1TS)
  [2] FW_CTRL_OUT0_SET_EMMC_RET0_PROXY — Sets the value of the corresponding bit in fw_ctrl_out SMS output bus. This bit is used by SOC to drive an AO signal that will eventually be expanded into a complementary pair (RET + RET_B) at the boundary of EMMC-PHY instance 0 (access R/W1TS)
  [1] FW_CTRL_OUT0_SET_IO_PM_CTRL_1_PROXY — This MMR bit is a W1ts bit field for MMR-bit-field FW_CTRL_OUT0.io_pm_ctrl1 (access R/W1TS)
  [0] FW_CTRL_OUT0_SET_IO_PM_CTRL_0_PROXY — This MMR bit is a W1ts bit field for MMR-bit-field FW_CTRL_OUT0.io_pm_ctrl0 (access R/W1TS)
0x16048 CFG0_FW_CTRL_OUT0_CLR_PROXY access not given
  [3] FW_CTRL_OUT0_CLR_EMMC_RET1_PROXY — Clears the value of the corresponding bit in fw_ctrl_out SMS output bus. This bit is used by SOC to drive an AO signal that will eventually be expanded into a complementary pair (RET + RET_B) at the boundary of EMMC-PHY instance1. (access R/W1TC)
  [2] FW_CTRL_OUT0_CLR_EMMC_RET0_PROXY — Clears the value of the corresponding bit in fw_ctrl_out SMS output bus. This bit is used by SOC to drive an AO signal that will eventually be expanded into a complementary pair (RET + RET_B) at the boundary of EMMC-PHY instance 0 (access R/W1TC)
  [1] FW_CTRL_OUT0_CLR_IO_PM_CTRL_1_PROXY — This MMR bit is a W1ts bit field for MMR-bit-field FW_CTRL_OUT0.io_pm_ctrl1 (access R/W1TC)
  [0] FW_CTRL_OUT0_CLR_IO_PM_CTRL_0_PROXY — This MMR bit is a W1ts bit field for MMR-bit-field FW_CTRL_OUT0.io_pm_ctrl0 (access R/W1TC)
0x16080 CFG0_PMCTRL_SYS_PROXY reset 0x10
  [4] PMCTRL_SYS_PMIC_EN_PROXY — PMIC enable. In order to write to this field, you need to write 1 in the same access to field pmic_en_we. NOTE: This MMR bit does not reflect any contribution from any debug related signal. 0 - Drives PMIC_EN output port to 0, unless there is an POWER-OFF inhibit condition due to Debug/Security 1 - Drives PMIC_EN output port to 1, if not already 1
0x16084 CFG0_PMCTRL_IO_0_PROXY access per field
  [25] PMCTRL_IO_0_IO_ISO_STATUS_0_PROXY ro — IO ISO Status 0 - IO isolation not active 1 - IO isolation active. Reflects value of SMS input port io_isoack coming back from IO pad ring
  [24] PMCTRL_IO_0_IO_ISO_CTRL_0_PROXY rw — IO ISO control. 0 - Turn off the IO isolation 1 - Turn on the IO isolation
  [16] PMCTRL_IO_0_GLOBAL_WUEN_0_PROXY rw — Global IO wakeup enable. This is a gating condition to all individual IO WUEN coming from control module. Gating is done in the Spinner logic. 0 - All individual IO WUEN are gated in the Spinner logic (override to 0). 1 - All individual IO WUEN from control module are going to IOs. Maps to SMS output port io_globalwkupen0 .
  [9] PMCTRL_IO_0_WUCLK_STATUS_0_PROXY ro — Reflects value of SMS input port io_wuclkack coming back from IO pad ring
  [8] PMCTRL_IO_0_WUCLK_CTRL_0_PROXY rw — Direct control on WUCLKIN signal to IO pad ring. 0 - WUCLKIN signal is driven to 0. IO wakeup daisy chain is functional as well as IO whose wakeup feature is enabled. 1 - WUCLKIN signal is driven to 1. IO wakeup daisy chain is reset and is latching current pad states and WUEN inputs
  [6] PMCTRL_IO_0_ISOBYBASS_OVR_0_PROXY rw — This MMR bit drives directly SMS output port io_isobypass0.
  [5] PMCTRL_IO_0_IO_ON_STATUS_0_PROXY ro — Gives the functional status of the IO ring. 0 - Part or all of the IOs are not in the ON state that is are in isolation state. 1 - All IOs are in the ON state. io_on_status = assign 1 if (io_iso == 0 & io_isoack==0 & io_iso_clk == 0 & io_isoclk_ack = 0 ) else 0;
  [4] PMCTRL_IO_0_ISOOVR_EXTEND_0_PROXY rw — Control for IO isolation extension This drives the SOC chain ISO-OVERRIDE global control. This bit drives directly the SMS output port io_isoovr0. At the SOC level it is used to enable when 1 or gate-off when 0, the individual ISOOR for each IO. This operates as a global enable/disable for the individual IOs. 0 - IO isolation is not extended. Transition happens as soon as automatic restore is completed. 1 - IO isolation is extended. The IOs whose ISOOVR bits have been individually set in their PADCFG MMRs will all get its IO isolation extended beyond the point when the initial IO daisy chain isolation is released.
  [1] PMCTRL_IO_0_ISOCLK_STATUS_0_PROXY ro — Reflects value of io_isoclkack coming back from IO pad ring.
  [0] PMCTRL_IO_0_ISOCLK_OVRD_0_PROXY rw — Override control on ISOCLKIN signal to IO pad ring. When not overridden this signal is controlled by hardware only. 0 - ISOCLKIN signal is not overriden. 1 - ISOCLKIN signal is overridden to active value (1).
0x16088 CFG0_PMCTRL_IO_1_PROXY access per field
  [25] PMCTRL_IO_1_IO_ISO_STATUS_1_PROXY ro — IO ISO Status 0 - IO isolation not active 1 - IO isolation active. Reflects value of SMS input port io_isoack coming back from IO pad ring
  [24] PMCTRL_IO_1_IO_ISO_CTRL_1_PROXY rw — IO ISO control. 0 - Turn off the IO isolation 1 - Turn on the IO isolation
  [16] PMCTRL_IO_1_GLOBAL_WUEN_1_PROXY rw — Global IO wakeup enable. This is a gating condition to all individual IO WUEN coming from control module. Gating is done in the Spinner logic. 0 - All individual IO WUEN are gated in the Spinner logic (override to 0). 1 - All individual IO WUEN from control module are going to IOs. Maps to SMS output port io_globalwkupen1 .
  [9] PMCTRL_IO_1_WUCLK_STATUS_1_PROXY ro — Reflects value of SMS input port io_wuclkack coming back from IO pad ring
  [8] PMCTRL_IO_1_WUCLK_CTRL_1_PROXY rw — Direct control on WUCLKIN signal to IO pad ring. 0 - WUCLKIN signal is driven to 0. IO wakeup daisy chain is functional as well as IO whose wakeup feature is enabled. 1 - WUCLKIN signal is driven to 1. IO wakeup daisy chain is reset and is latching current pad states and WUEN inputs
  [6] PMCTRL_IO_1_ISOBYBASS_OVR_1_PROXY rw — This MMR bit drives directly SMS output port io_isobypassundefined.
  [5] PMCTRL_IO_1_IO_ON_STATUS_1_PROXY ro — Gives the functional status of the IO ring. 0 - Part or all of the IOs are not in the ON state that is are in isolation state. 1 - All IOs are in the ON state. io_on_status = assign 1 if (io_iso == 0 & io_isoack==0 & io_iso_clk == 0 & io_isoclk_ack = 0 ) else 0;
  [4] PMCTRL_IO_1_ISOOVR_EXTEND_1_PROXY rw — Control for IO isolation extension This drives the SOC chain ISO-OVERRIDE global control. This bit drives directly the SMS output port io_isoovrundefined. At the SOC level it is used to enable when 1 or gate-off when 0, the individual ISOOR for each IO. This operates as a global enable/disable for the individual IOs. 0 - IO isolation is not extended. Transition happens as soon as automatic restore is completed. 1 - IO isolation is extended. The IOs whose ISOOVR bits have been individually set in their PADCFG MMRs will all get its IO isolation extended beyond the point when the initial IO daisy chain isolation is released.
  [1] PMCTRL_IO_1_ISOCLK_STATUS_1_PROXY ro — Reflects value of io_isoclkack coming back from IO pad ring.
  [0] PMCTRL_IO_1_ISOCLK_OVRD_1_PROXY rw — Override control on ISOCLKIN signal to IO pad ring. When not overridden this signal is controlled by hardware only. 0 - ISOCLKIN signal is not overriden. 1 - ISOCLKIN signal is overridden to active value (1).
0x16300 CFG0_PM_PERMISSION_PROXY ro
  [0] PM_PERMISSION_DEBUG_ACTIVE_PROXY — Debug mode activated Tells PM-FW that it should not power-OFF supplies externally. The debugger being active should also cause the SMS hardware to override the external rail state during deeperSleep by forcing high the pmic_en output. In addition to forcing the rails of all SOC supplies on, this bit will also cause the VDD_CORE domain in SOCs with it, to get out of POR-reset and wake-up the Debugss so that its JTAG interface can connect. When this MMR bit is set, PM Hardware FSM should enter only into low power modes LPM0 to LPM1, but should not go into LPM2 to LPM4 where it clock-gates or power downs the clock sources. The debug_activated input set to '1' will also cause the M4 to get out of LPMs and exit WFI, since there is an interrupt allocated to that input port (debug_activated), after the attached debug is disconnected from the SOC the interrupt associated to debug_deactivated will be triggered by IceMelter and that should cause the M4 to exit the debug_activated interrupt service routine (ISR), and , if no other wake-up event is present then when debug_deactivated goes to '0' the PM-FW will do any required clearing/cleaning as part of the ISR set the M4 in WFI, and return to the low power state as defined in PMCTRL_SYS.LPM[2:0] bits. If instead of an attached debugger being present we have a software driven debug, then the interrupt that could be triggered instead of debug_activated will be debug_forceactive_int and causing same response as with debug_activated input/interrupt. In this case as part of the debug_activated ISR epilog the M4 will go back to WFI, , and return to the low power state as defined in PMCTRL_SYS.LPM[2:0] bits. 0 - Debug not activated 1 - Debug activated
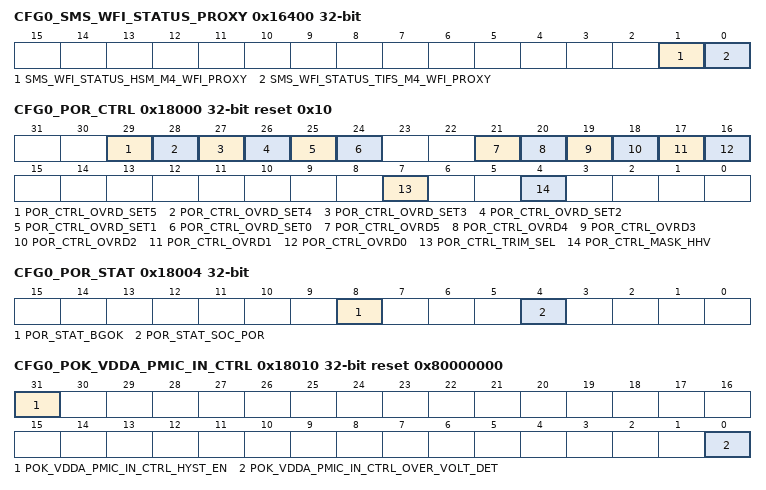
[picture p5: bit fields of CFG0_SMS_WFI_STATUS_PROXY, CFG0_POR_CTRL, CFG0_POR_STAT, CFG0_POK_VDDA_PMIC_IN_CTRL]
0x16400 CFG0_SMS_WFI_STATUS_PROXY ro
  [1] SMS_WFI_STATUS_HSM_M4_WFI_PROXY — Indicates WFI status of the HSM M4 processor in SMS 0 - Normal operation 1 - M4 is in WFI state
  [0] SMS_WFI_STATUS_TIFS_M4_WFI_PROXY — Indicates WFI status of the TIFS M4 processor in SMS 0 - Normal operation 1 - M4 is in WFI state
{0x17100+4i} CFG0_CLAIMREG_P5_R{i} (i=0..8)
  [31:0] CLAIMREG_P5_R{i} — Claim bits for Partition 5
0x18000 CFG0_POR_CTRL reset 0x10
  [29] POR_CTRL_OVRD_SET5 — Reserved override set
  [28] POR_CTRL_OVRD_SET4 — POKLVB override set
  [27] POR_CTRL_OVRD_SET3 — POKLVA override set
  [26] POR_CTRL_OVRD_SET2 — POKHV override set
  [25] POR_CTRL_OVRD_SET1 — BGOK override set
  [24] POR_CTRL_OVRD_SET0 — PORHV override set
  [21] POR_CTRL_OVRD5 — Reserved override enable
  [20] POR_CTRL_OVRD4 — POKLVB override enable
  [19] POR_CTRL_OVRD3 — POKLVA override enable
  [18] POR_CTRL_OVRD2 — POKHV override enable
  [17] POR_CTRL_OVRD1 — BGOK override enable
  [16] POR_CTRL_OVRD0 — PORHV override enable
  [7] POR_CTRL_TRIM_SEL — POR Trim Select 0 - Trim selections for Bandgap and POKs come from HHV defaults 1 - Trim selections for Bandgap and POKs come from POR_BANDGAP_CTRL and POR_POKxxx_CTRL registers
  [4] POR_CTRL_MASK_HHV — Mask HHV/SOC_PORz outputs when applying new trim values
0x18004 CFG0_POR_STAT ro
  [8] POR_STAT_BGOK — Bandgap OK status
  [4] POR_STAT_SOC_POR — POR module status 0 - Module is in functional mode 1 - Module is in reset mode
0x18010 CFG0_POK_VDDA_PMIC_IN_CTRL reset 0x80000000
  [31] POK_VDDA_PMIC_IN_CTRL_HYST_EN — Enable POK hysteresis
  [0] POK_VDDA_PMIC_IN_CTRL_OVER_VOLT_DET — Over / under voltage detection mode 0 - Under voltage detection 1 - Over voltage detection
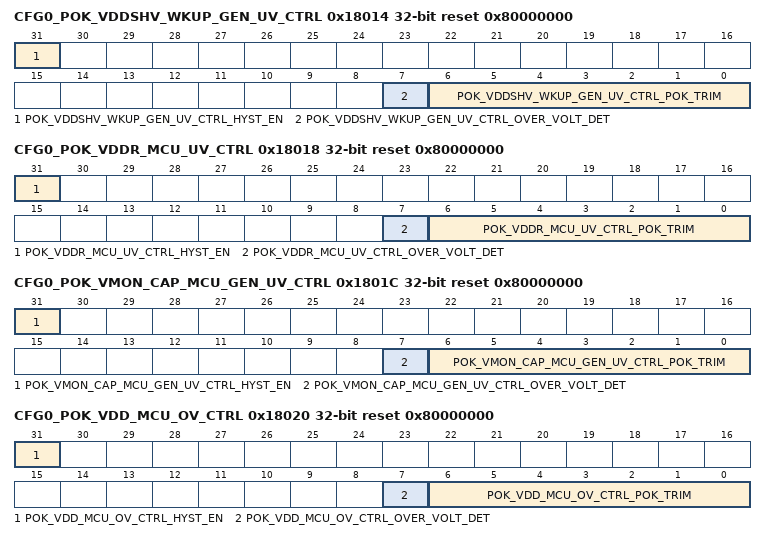
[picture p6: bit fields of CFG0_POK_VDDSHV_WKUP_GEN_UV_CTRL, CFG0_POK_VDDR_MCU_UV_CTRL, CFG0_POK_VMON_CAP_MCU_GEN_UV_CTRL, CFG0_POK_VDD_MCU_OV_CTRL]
0x18014 CFG0_POK_VDDSHV_WKUP_GEN_UV_CTRL reset 0x80000000
  [31] POK_VDDSHV_WKUP_GEN_UV_CTRL_HYST_EN — Enable POK hysteresis
  [7] POK_VDDSHV_WKUP_GEN_UV_CTRL_OVER_VOLT_DET — Over / under voltage detection mode 0 - Under voltage detection 1 - Over voltage detection
  [6:0] POK_VDDSHV_WKUP_GEN_UV_CTRL_POK_TRIM — POK trim bits. These bits are used to trim the comparator threshold voltage. See POK spec and J7 efuse spec for details
0x18018 CFG0_POK_VDDR_MCU_UV_CTRL reset 0x80000000
  [31] POK_VDDR_MCU_UV_CTRL_HYST_EN — Enable POK hysteresis
  [7] POK_VDDR_MCU_UV_CTRL_OVER_VOLT_DET — Over / under voltage detection mode 0 - Under voltage detection 1 - Over voltage detection
  [6:0] POK_VDDR_MCU_UV_CTRL_POK_TRIM — POK trim bits. These bits are used to trim the comparator threshold voltage. See POK spec and J7 efuse spec for details
0x1801C CFG0_POK_VMON_CAP_MCU_GEN_UV_CTRL reset 0x80000000
  [31] POK_VMON_CAP_MCU_GEN_UV_CTRL_HYST_EN — Enable POK hysteresis
  [7] POK_VMON_CAP_MCU_GEN_UV_CTRL_OVER_VOLT_DET — Over / under voltage detection mode 0 - Under voltage detection 1 - Over voltage detection
  [6:0] POK_VMON_CAP_MCU_GEN_UV_CTRL_POK_TRIM — POK trim bits. These bits are used to trim the comparator threshold voltage. See POK spec and efuse spec for details
0x18020 CFG0_POK_VDD_MCU_OV_CTRL reset 0x80000000
  [31] POK_VDD_MCU_OV_CTRL_HYST_EN — Enable POK hysteresis
  [7] POK_VDD_MCU_OV_CTRL_OVER_VOLT_DET — Over / under voltage detection mode 0 - Under voltage detection 1 - Over voltage detection
  [6:0] POK_VDD_MCU_OV_CTRL_POK_TRIM — POK trim bits. These bits are used to trim the comparator threshold voltage. See POK spec and J7 efuse spec for details
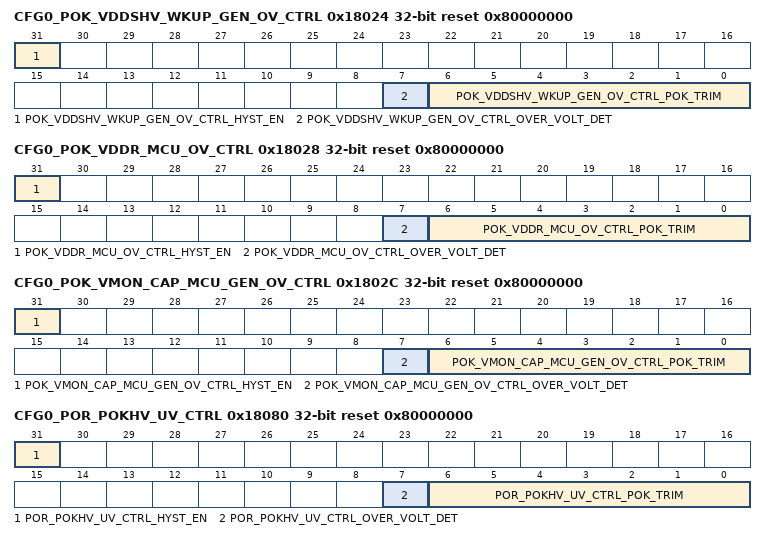
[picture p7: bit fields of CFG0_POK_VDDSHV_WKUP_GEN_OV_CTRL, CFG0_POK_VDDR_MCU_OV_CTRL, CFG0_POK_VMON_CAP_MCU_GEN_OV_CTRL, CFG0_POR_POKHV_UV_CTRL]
0x18024 CFG0_POK_VDDSHV_WKUP_GEN_OV_CTRL reset 0x80000000
  [31] POK_VDDSHV_WKUP_GEN_OV_CTRL_HYST_EN — Enable POK hysteresis
  [7] POK_VDDSHV_WKUP_GEN_OV_CTRL_OVER_VOLT_DET — Over / under voltage detection mode 0 - Under voltage detection 1 - Over voltage detection
  [6:0] POK_VDDSHV_WKUP_GEN_OV_CTRL_POK_TRIM — POK trim bits. These bits are used to trim the comparator threshold voltage. See POK spec and J7 efuse spec for details
0x18028 CFG0_POK_VDDR_MCU_OV_CTRL reset 0x80000000
  [31] POK_VDDR_MCU_OV_CTRL_HYST_EN — Enable POK hysteresis
  [7] POK_VDDR_MCU_OV_CTRL_OVER_VOLT_DET — Over / under voltage detection mode 0 - Under voltage detection 1 - Over voltage detection
  [6:0] POK_VDDR_MCU_OV_CTRL_POK_TRIM — POK trim bits. These bits are used to trim the comparator threshold voltage. See POK spec and J7 efuse spec for details
0x1802C CFG0_POK_VMON_CAP_MCU_GEN_OV_CTRL reset 0x80000000
  [31] POK_VMON_CAP_MCU_GEN_OV_CTRL_HYST_EN — Enable POK hysteresis
  [7] POK_VMON_CAP_MCU_GEN_OV_CTRL_OVER_VOLT_DET — Over / under voltage detection mode 0 - Under voltage detection 1 - Over voltage detection
  [6:0] POK_VMON_CAP_MCU_GEN_OV_CTRL_POK_TRIM — POK trim bits. These bits are used to trim the comparator threshold voltage. See POK spec and efuse spec for details
0x18070 CFG0_MAIN_VDOM_CTRL
  [0] MAIN_VDOM_CTRL_MAIN_VD_OFF — MAIN deep sleep isolation enable. This bit should be set prior to powering off the MAIN voltage domain to ensure proper signal isolation.
0x18080 CFG0_POR_POKHV_UV_CTRL reset 0x80000000
  [31] POR_POKHV_UV_CTRL_HYST_EN — Enable POK hysteresis
  [7] POR_POKHV_UV_CTRL_OVER_VOLT_DET — Over / under voltage detection mode 0 - Under voltage detection 1 - Over voltage detection
  [6:0] POR_POKHV_UV_CTRL_POK_TRIM — POK trim bits. These bits are used to trim the comparator threshold voltage. See POK spec and J7 efuse spec for details
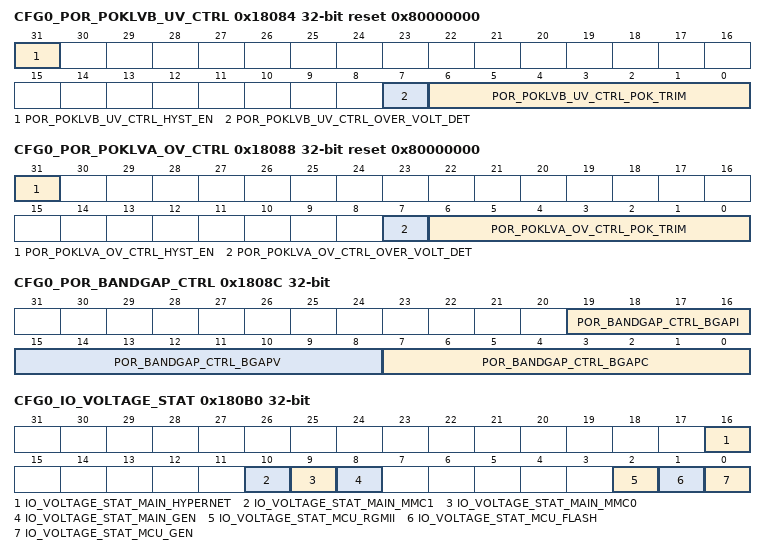
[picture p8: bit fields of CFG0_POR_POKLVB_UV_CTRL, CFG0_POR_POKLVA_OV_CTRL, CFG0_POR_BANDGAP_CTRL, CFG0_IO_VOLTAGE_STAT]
0x18084 CFG0_POR_POKLVB_UV_CTRL reset 0x80000000
  [31] POR_POKLVB_UV_CTRL_HYST_EN — Enable POK hysteresis
  [7] POR_POKLVB_UV_CTRL_OVER_VOLT_DET — Over / under voltage detection mode 0 - Under voltage detection 1 - Over voltage detection
  [6:0] POR_POKLVB_UV_CTRL_POK_TRIM — POK trim bits. These bits are used to trim the comparator threshold voltage. See POK spec and J7 efuse spec for details
0x18088 CFG0_POR_POKLVA_OV_CTRL reset 0x80000000
  [31] POR_POKLVA_OV_CTRL_HYST_EN — Enable POK hysteresis
  [7] POR_POKLVA_OV_CTRL_OVER_VOLT_DET — Over / under voltage detection mode 0 - Under voltage detection 1 - Over voltage detection
  [6:0] POR_POKLVA_OV_CTRL_POK_TRIM — POK trim bits. These bits are used to trim the comparator threshold voltage. See POK spec and J7 efuse spec for details
0x1808C CFG0_POR_BANDGAP_CTRL
  [19:16] POR_BANDGAP_CTRL_BGAPI — Bandgap output current trim bits
  [15:8] POR_BANDGAP_CTRL_BGAPV — Bandgap output voltage magnitude trim bits
  [7:0] POR_BANDGAP_CTRL_BGAPC — Bandgap slope trim bits. Bit7 is used to calculate the offset
0x180A0 CFG0_TEMP_DIODE_TRIM
  [13:0] TEMP_DIODE_TRIM_TRIM — Sets the diode non-ideality factor (n), starting from 100th place decimal and going down
0x180B0 CFG0_IO_VOLTAGE_STAT ro
  [16] IO_VOLTAGE_STAT_MAIN_HYPERNET — Indicates the voltage for the HYPERNET I/O group 0 - I/O group is set for 1.8V 1 - I/O group is set for 3.3V
  [10] IO_VOLTAGE_STAT_MAIN_MMC1 — Indicates the voltage for the MMC1 I/O group 0 - I/O group is set for 1.8V 1 - I/O group is set for 3.3V
  [9] IO_VOLTAGE_STAT_MAIN_MMC0 — Indicates the voltage for the MMC0 I/O group 0 - I/O group is set for 1.8V 1 - I/O group is set for 3.3V
  [8] IO_VOLTAGE_STAT_MAIN_GEN — Indicates the voltage for the General I/O group 0 - I/O group is set for 1.8V 1 - I/O group is set for 3.3V
  [2] IO_VOLTAGE_STAT_MCU_RGMII — Indicates the voltage for the MCU CPSW2G RGMII I/O group 0 - I/O group is set for 1.8V 1 - I/O group is set for 3.3V
  [1] IO_VOLTAGE_STAT_MCU_FLASH — Indicates the voltage for the MCU Flash I/O group 0 - I/O group is set for 1.8V 1 - I/O group is set for 3.3V
  [0] IO_VOLTAGE_STAT_MCU_GEN — Indicates the voltage for the MCU General I/O group 0 - I/O group is set for 1.8V 1 - I/O group is set for 3.3V
0x18104 CFG0_MAIN_POR_TO_CTRL
  [2:0] MAIN_POR_TO_CTRL_TIMEOUT_PER — MAIN PORz hardware timeout period. During normal operation, the assertion of a MAIN Domain PORz generates a reset request interrupt to the DMSC. The DMSC then performs steps to properly isolate the MAIN Domain before the actual reset is performed. A hardware timeout mechanism is provided to ensure that the PORz gets propagated to the MAIN Domain in the event that a error prevents the DMSC from completing the reset isolation. Field values (others are reserved): 3'b000 - Immediate 3'b001 - 100 microsec 3'b010 - 200 microsec 3'b011 - 300 microsec 3'b100 - 400 microsec 3'b101 - 500 microsec
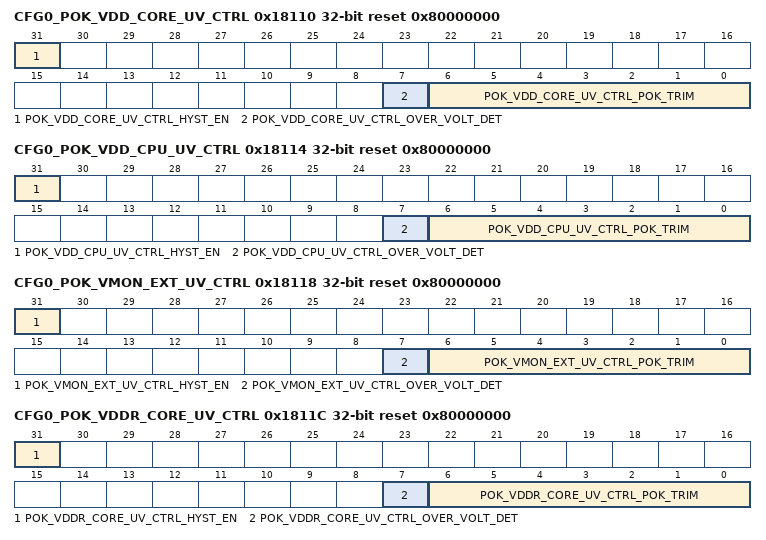
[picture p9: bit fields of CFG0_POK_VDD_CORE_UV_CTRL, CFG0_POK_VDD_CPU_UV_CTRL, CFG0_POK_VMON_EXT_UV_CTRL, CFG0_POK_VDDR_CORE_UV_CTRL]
0x18110 CFG0_POK_VDD_CORE_UV_CTRL reset 0x80000000
  [31] POK_VDD_CORE_UV_CTRL_HYST_EN — Enable POK hysteresis
  [7] POK_VDD_CORE_UV_CTRL_OVER_VOLT_DET — Over / under voltage detection mode 0 - Under voltage detection 1 - Over voltage detection
  [6:0] POK_VDD_CORE_UV_CTRL_POK_TRIM — POK trim bits. These bits are used to trim the comparator threshold voltage. See POK spec and efuse spec for details
0x18114 CFG0_POK_VDD_CPU_UV_CTRL reset 0x80000000
  [31] POK_VDD_CPU_UV_CTRL_HYST_EN — Enable POK hysteresis
  [7] POK_VDD_CPU_UV_CTRL_OVER_VOLT_DET — Over / under voltage detection mode 0 - Under voltage detection 1 - Over voltage detection
  [6:0] POK_VDD_CPU_UV_CTRL_POK_TRIM — POK trim bits. These bits are used to trim the comparator threshold voltage. See POK spec and efuse spec for details
0x18118 CFG0_POK_VMON_EXT_UV_CTRL reset 0x80000000
  [31] POK_VMON_EXT_UV_CTRL_HYST_EN — Enable POK hysteresis
  [7] POK_VMON_EXT_UV_CTRL_OVER_VOLT_DET — Over / under voltage detection mode 0 - Under voltage detection 1 - Over voltage detection
  [6:0] POK_VMON_EXT_UV_CTRL_POK_TRIM — POK trim bits. These bits are used to trim the comparator threshold voltage. See POK spec and efuse spec for details
0x1811C CFG0_POK_VDDR_CORE_UV_CTRL reset 0x80000000
  [31] POK_VDDR_CORE_UV_CTRL_HYST_EN — Enable POK hysteresis
  [7] POK_VDDR_CORE_UV_CTRL_OVER_VOLT_DET — Over / under voltage detection mode 0 - Under voltage detection 1 - Over voltage detection
  [6:0] POK_VDDR_CORE_UV_CTRL_POK_TRIM — POK trim bits. These bits are used to trim the comparator threshold voltage. See POK spec and efuse spec for details
